# bcm2711_lpa register map
Vendor: BROADCOM; Series: BCM2711; File version: A
CPU: CA72 r0p0, little endian, MPU, FPU, 2 interrupt priority bits
Registers are 32-bit, read-write, reset 0x0 unless marked. A register's access mark holds for its fields unless they carry their own. Offsets are from the block's base; [hi:lo] are bit positions; lines under a group give offsets from that group; {n}, {i} and the like mark numbered series; 'fields as' and 'values as' point back to an identical list.

## GIC_CPU — ARM GIC-400 Generic Interrupt Controller CPU Interface
Base 0xFF842000
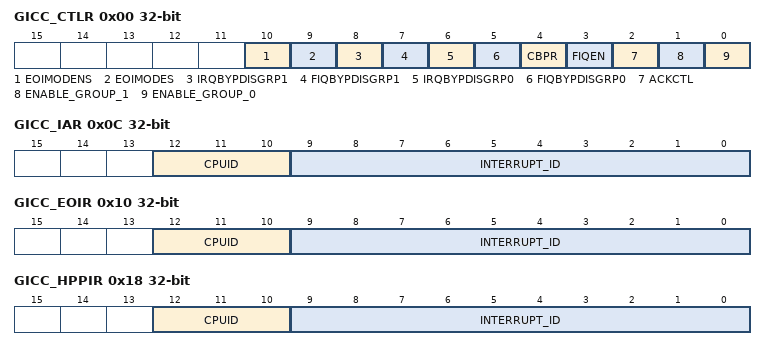
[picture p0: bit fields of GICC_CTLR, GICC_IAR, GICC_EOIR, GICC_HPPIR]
0x00 GICC_CTLR — CPU Interface Control
  [10] EOIMODENS — Non-Secure EOIR does priority drop. DIR does deactivate.
  [9] EOIMODES — Secure EOIR does priority drop. DIR does deactivate.
  [8] IRQBYPDISGRP1 — Alias of group 1 IRQ bypass disable
  [7] FIQBYPDISGRP1 — Alias of group 1 FIQ bypass disable
  [6] IRQBYPDISGRP0 — Bypass IRQ is not signaled to processor
  [5] FIQBYPDISGRP0 — Bypass FIQ is not signaled to processor
  [4] CBPR — Common control of interrupts through GICC_BPR
  [3] FIQEN — Group 0 triggers FIQ
  [2] ACKCTL — Whether a read of IAR acknowledges the interrupt
  [1] ENABLE_GROUP_1 — Enable signaling of group 1
  [0] ENABLE_GROUP_0 — Enable signaling of group 0
0x04 GICC_PMR — Interrupt Priority Mask
  [7:0] PRIORITY — Interrupts with a higher number are not signaled
0x08 GICC_BPR — Binary Point
  [2:0] BINARY_POINT — Split point between group priority and subpriority
0x0C GICC_IAR ro — Interrupt Acknowledge
  [12:10] CPUID — CPUID that requested a software interrupt, 0 otherwise
  [9:0] INTERRUPT_ID
0x10 GICC_EOIR wo — End of Interrupt
  fields as GICC_IAR
0x14 GICC_RPR ro — Running Priority
  [7:0] PRIORITY — Current running priority
0x18 GICC_HPPIR — Highest Priority Pending Interrupt
  [12:10] CPUID — CPUID that requested a software interrupt, 0 otherwise
  [9:0] INTERRUPT_ID — Pending Interrupt ID
0x1C GICC_ABPR — Aliased Binary Point
  fields as GICC_BPR
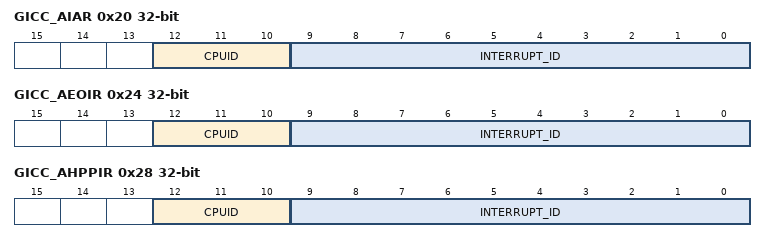
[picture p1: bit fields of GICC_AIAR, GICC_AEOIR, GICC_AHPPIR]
0x20 GICC_AIAR ro — Aliased Interrupt Acknowledge
  fields as GICC_IAR
0x24 GICC_AEOIR wo — Aliased End of Interrupt
  fields as GICC_IAR
0x28 GICC_AHPPIR ro — Aliased Highest Priority Pending Interrupt
  fields as GICC_HPPIR
0xD0 GICC_APR0 — Active Priority
0xE0 GICC_NSAPR0 — Non-Secure Active Priority
0xFC GICC_IIDR reset 0x202143B — CPU Interface Identification Register
  [31:0] ID
    0x202143B=VALID (ID is valid); other=INVALID (ID is *NOT* valid)
0x1000 GICC_DIR wo — Deactivate Interrupt

## USB_OTG_HOST — USB on the go high speed
Base 0xFE980400
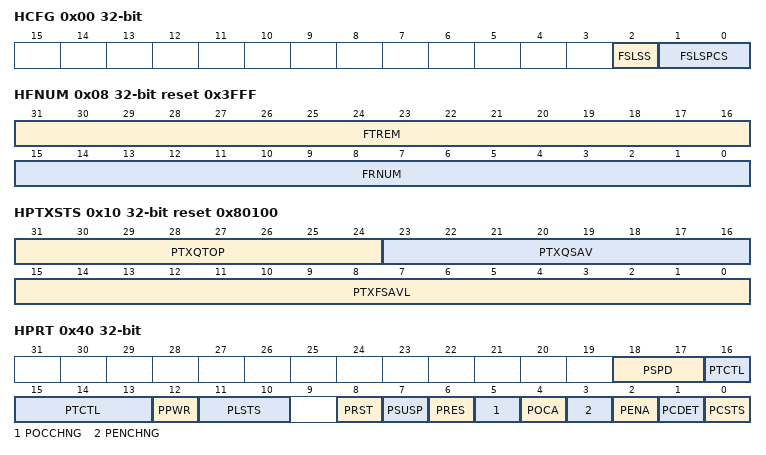
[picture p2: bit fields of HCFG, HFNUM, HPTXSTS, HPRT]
0x00 HCFG access per field — OTG_HS host configuration register
  [2] FSLSS ro — FS- and LS-only support
  [1:0] FSLSPCS rw — FS/LS PHY clock select
0x04 HFIR reset 0xEA60 — OTG_HS Host frame interval register
  [15:0] FRIVL — Frame interval
0x08 HFNUM ro reset 0x3FFF — OTG_HS host frame number/frame time remaining register
  [31:16] FTREM — Frame time remaining
  [15:0] FRNUM — Frame number
0x10 HPTXSTS access per field reset 0x80100 — Host periodic transmit FIFO/queue status register
  [31:24] PTXQTOP ro — Top of the periodic transmit request queue
  [23:16] PTXQSAV ro — Periodic transmit request queue space available
  [15:0] PTXFSAVL rw — Periodic transmit data FIFO space available
0x14 HAINT ro — OTG_HS Host all channels interrupt register
  [15:0] HAINT — Channel interrupts
0x18 HAINTMSK — OTG_HS host all channels interrupt mask register
  [15:0] HAINTM — Channel interrupt mask
0x40 HPRT access per field — OTG_HS host port control and status register
  [18:17] PSPD ro — Port speed
  [16:13] PTCTL rw — Port test control
  [12] PPWR rw — Port power
  [11:10] PLSTS ro — Port line status
  [8] PRST rw — Port reset
  [7] PSUSP rw — Port suspend
  [6] PRES rw — Port resume
  [5] POCCHNG rw — Port overcurrent change
  [4] POCA ro — Port overcurrent active
  [3] PENCHNG rw — Port enable/disable change
  [2] PENA rw — Port enable
  [1] PCDET rw — Port connect detected
  [0] PCSTS ro — Port connect status
{0x100+0x20*i} HOST_CHANNEL{i} (i=0..11) group — Host channel {i}
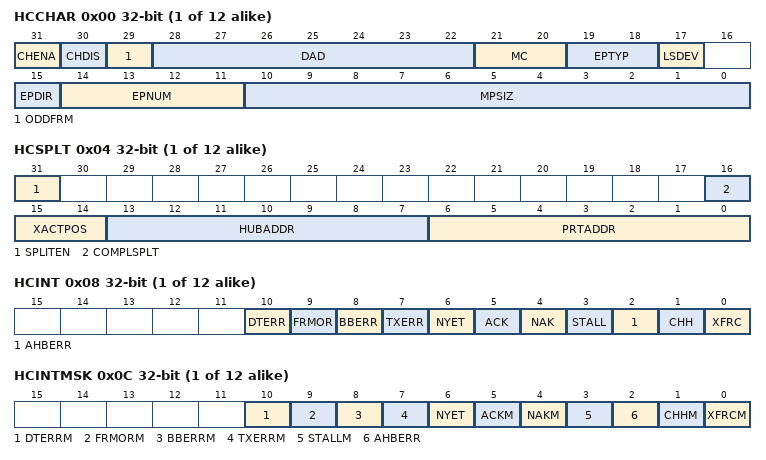
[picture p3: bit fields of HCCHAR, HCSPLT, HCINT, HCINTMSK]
  0x00 HCCHAR — Characteristics register
    [31] CHENA — Channel enable
    [30] CHDIS — Channel disable
    [29] ODDFRM — Odd frame
    [28:22] DAD — Device address
    [21:20] MC — Multi Count (MC) / Error Count (EC)
    [19:18] EPTYP — Endpoint type
    [17] LSDEV — Low-speed device
    [15] EPDIR — Endpoint direction
    [14:11] EPNUM — Endpoint number
    [10:0] MPSIZ — Maximum packet size
  0x04 HCSPLT — Split control register
    [31] SPLITEN — Split enable
    [16] COMPLSPLT — Do complete split
    [15:14] XACTPOS
    [13:7] HUBADDR — Hub address
    [6:0] PRTADDR — Port address
  0x08 HCINT — Interrupt register
    [10] DTERR — Data toggle error
    [9] FRMOR — Frame overrun
    [8] BBERR — Babble error
    [7] TXERR — Transaction error
    [6] NYET — Response received interrupt
    [5] ACK — ACK response received/transmitted interrupt
    [4] NAK — NAK response received interrupt
    [3] STALL — STALL response received interrupt
    [2] AHBERR — AHB error
    [1] CHH — Channel halted
    [0] XFRC — Transfer completed
  0x0C HCINTMSK — Interrupt mask
    [10] DTERRM — Data toggle error mask
    [9] FRMORM — Frame overrun mask
    [8] BBERRM — Babble error mask
    [7] TXERRM — Transaction error mask
    [6] NYET — response received interrupt mask
    [5] ACKM — ACK response received/transmitted interrupt mask
    [4] NAKM — NAK response received interrupt mask
    [3] STALLM — STALL response received interrupt mask
    [2] AHBERR — AHB error
    [1] CHHM — Channel halted mask
    [0] XFRCM — Transfer completed mask
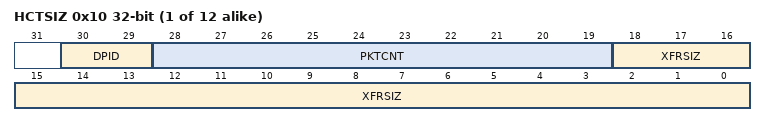
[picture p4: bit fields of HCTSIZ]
  0x10 HCTSIZ — Transfer size
    [30:29] DPID — Data PID
    [28:19] PKTCNT — Packet count
    [18:0] XFRSIZ — Transfer size
  0x14 HCDMA — DMA address
    [31:0] DMAADDR

## USB_OTG_PWRCLK — USB on the go high speed power control
Base 0xFE980E00
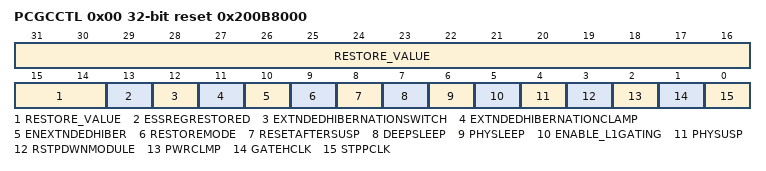
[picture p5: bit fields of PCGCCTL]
0x00 PCGCCTL reset 0x200B8000 — power and clock gating control
  [31:14] RESTORE_VALUE
  [13] ESSREGRESTORED — Essential register values restored
  [12] EXTNDEDHIBERNATIONSWITCH — Extended hibernation switch
  [11] EXTNDEDHIBERNATIONCLAMP — Extended hibernation clamp
  [10] ENEXTNDEDHIBER — Enable extended hibernation
  [9] RESTOREMODE
  [8] RESETAFTERSUSP — Reset after suspend
  [7] DEEPSLEEP — PHY is in deep sleep
  [6] PHYSLEEP — PHY is in sleep mode
  [5] ENABLE_L1GATING — Enable sleep clock gating
  [4] PHYSUSP — PHY Suspended
  [3] RSTPDWNMODULE — Power down modules
  [2] PWRCLMP — Power clamp
  [1] GATEHCLK
  [0] STPPCLK — Stop PHY clock
